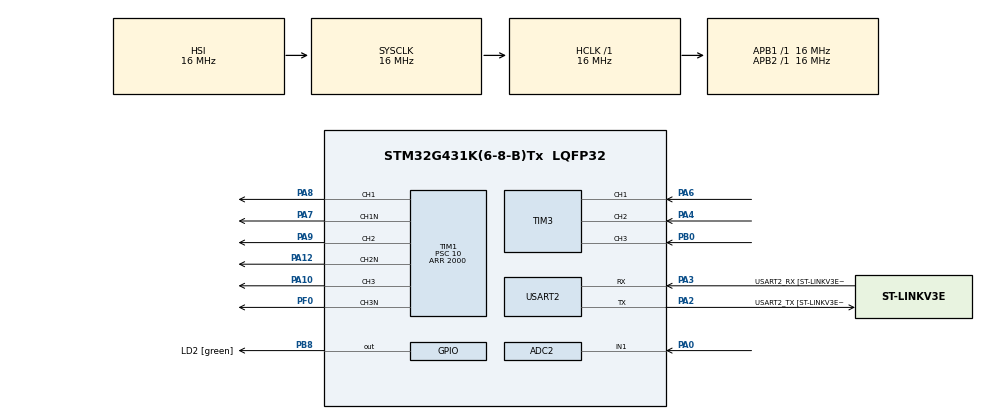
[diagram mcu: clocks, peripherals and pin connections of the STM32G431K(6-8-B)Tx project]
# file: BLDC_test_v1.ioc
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ADC2.Channel-0\#ChannelRegularConversion=ADC_CHANNEL_1
ADC2.NbrOfConversionFlag=1
ADC2.OffsetNumber-0\#ChannelRegularConversion=ADC_OFFSET_NONE
ADC2.Rank-0\#ChannelRegularConversion=1
ADC2.SamplingTime-0\#ChannelRegularConversion=ADC_SAMPLETIME_2CYCLES_5
Dma.Request0=TIM1_CH1
Dma.Request1=TIM1_CH2
Dma.TIM1_CH1.0.Direction=DMA_MEMORY_TO_PERIPH
Dma.TIM1_CH1.0.EventEnable=DISABLE
Dma.TIM1_CH1.0.Instance=DMA1_Channel1
Dma.TIM1_CH1.0.MemDataAlignment=DMA_MDATAALIGN_HALFWORD
Dma.TIM1_CH1.0.MemInc=DMA_MINC_ENABLE
Dma.TIM1_CH1.0.Mode=DMA_CIRCULAR
Dma.TIM1_CH1.0.PeriphDataAlignment=DMA_PDATAALIGN_HALFWORD
Dma.TIM1_CH1.0.PeriphInc=DMA_PINC_DISABLE
Dma.TIM1_CH1.0.Polarity=HAL_DMAMUX_REQ_GEN_RISING
Dma.TIM1_CH1.0.Priority=DMA_PRIORITY_LOW
Dma.TIM1_CH1.0.RequestNumber=1
Dma.TIM1_CH1.0.SignalID=NONE
Dma.TIM1_CH1.0.SyncEnable=ENABLE
Dma.TIM1_CH1.0.SyncPolarity=HAL_DMAMUX_SYNC_RISING
Dma.TIM1_CH1.0.SyncRequestNumber=1
Dma.TIM1_CH1.0.SyncSignalID=NONE
Dma.TIM1_CH2.1.Direction=DMA_MEMORY_TO_PERIPH
Dma.TIM1_CH2.1.EventEnable=DISABLE
Dma.TIM1_CH2.1.Instance=DMA1_Channel2
Dma.TIM1_CH2.1.MemDataAlignment=DMA_MDATAALIGN_HALFWORD
Dma.TIM1_CH2.1.MemInc=DMA_MINC_ENABLE
Dma.TIM1_CH2.1.Mode=DMA_NORMAL
Dma.TIM1_CH2.1.PeriphDataAlignment=DMA_PDATAALIGN_HALFWORD
Dma.TIM1_CH2.1.PeriphInc=DMA_PINC_DISABLE
Dma.TIM1_CH2.1.Polarity=HAL_DMAMUX_REQ_GEN_RISING
Dma.TIM1_CH2.1.Priority=DMA_PRIORITY_LOW
Dma.TIM1_CH2.1.RequestNumber=1
Dma.TIM1_CH2.1.SignalID=NONE
Dma.TIM1_CH2.1.SyncEnable=ENABLE
Dma.TIM1_CH2.1.SyncPolarity=HAL_DMAMUX_SYNC_RISING
Dma.TIM1_CH2.1.SyncRequestNumber=1
Dma.TIM1_CH2.1.SyncSignalID=NONE
Mcu.Family=STM32G4
Mcu.Name=STM32G431K(6-8-B)Tx
Mcu.Package=LQFP32
NVIC.DMA1_Channel1_IRQn=true\:0\:0\:false\:false\:true\:false\:true\:true
NVIC.DMA1_Channel2_IRQn=true\:0\:0\:false\:false\:true\:false\:true\:true
NVIC.DMAMUX_OVR_IRQn=true\:0\:0\:false\:false\:true\:false\:true\:true
NVIC.PriorityGroup=NVIC_PRIORITYGROUP_4
PA0.Mode=IN1-Single-Ended
PA0.Signal=ADC2_IN1
PA10.Signal=S_TIM1_CH3
PA12.Mode=PWM Generation2 CH2 CH2N
PA12.Signal=TIM1_CH2N
PA13.GPIO_Label=T_SWDIO
PA13.Mode=Serial_Wire
PA13.Signal=SYS_JTMS-SWDIO
PA14.GPIO_Label=T_SWCLK
PA14.Mode=Serial_Wire
PA14.Signal=SYS_JTCK-SWCLK
PA2.GPIO_Label=USART2_TX [ST-LINKV3E_VCP_RX]
PA2.Mode=Asynchronous
PA2.Signal=USART2_TX
PA3.GPIO_Label=USART2_RX [ST-LINKV3E_VCP_TX]
PA3.Mode=Asynchronous
PA3.Signal=USART2_RX
PA4.Signal=S_TIM3_CH2
PA6.Signal=S_TIM3_CH1
PA7.Mode=PWM Generation1 CH1 CH1N
PA7.Signal=TIM1_CH1N
PA8.Signal=S_TIM1_CH1
PA9.Signal=S_TIM1_CH2
PB0.Signal=S_TIM3_CH3
PB3.GPIO_Label=T_SWO
PB3.Signal=SYS_JTDO-SWO
PB8-BOOT0.GPIO_Label=LD2 [green]
PB8-BOOT0.Signal=GPIO_Output
PF0-OSC_IN.Mode=PWM Generation3 CH3 CH3N
PF0-OSC_IN.Signal=TIM1_CH3N
ProjectManager.HeapSize=0x200
ProjectManager.StackSize=0x400
ProjectManager.TargetToolchain=STM32CubeIDE
RCC.ADC12Freq_Value=16000000
RCC.AHBFreq_Value=16000000
RCC.APB1Freq_Value=16000000
RCC.APB1TimFreq_Value=16000000
RCC.APB2Freq_Value=16000000
RCC.APB2TimFreq_Value=16000000
RCC.CortexFreq_Value=16000000
RCC.EXTERNAL_CLOCK_VALUE=12288000
RCC.HCLKFreq_Value=16000000
RCC.HSE_VALUE=8000000
RCC.HSI48_VALUE=48000000
RCC.HSI_VALUE=16000000
RCC.LSE_VALUE=32768
RCC.PLLM=RCC_PLLM_DIV4
RCC.PLLN=85
RCC.SYSCLKFreq_VALUE=16000000
RCC.USBFreq_Value=170000000
RCC.VCOOutputFreq_Value=340000000
SH.S_TIM1_CH1.0=TIM1_CH1,PWM Generation1 CH1 CH1N
SH.S_TIM1_CH2.0=TIM1_CH2,PWM Generation2 CH2 CH2N
SH.S_TIM1_CH3.0=TIM1_CH3,PWM Generation3 CH3 CH3N
SH.S_TIM3_CH1.0=TIM3_CH1,Xored_Inputs_Hall_Sensor_Interface
SH.S_TIM3_CH2.0=TIM3_CH2,Xored_Inputs_Hall_Sensor_Interface
SH.S_TIM3_CH3.0=TIM3_CH3,Xored_Inputs_Hall_Sensor_Interface
TIM1.AutoReloadPreload=TIM_AUTORELOAD_PRELOAD_ENABLE
TIM1.Channel-PWM\ Generation1\ CH1\ CH1N=TIM_CHANNEL_1
TIM1.Channel-PWM\ Generation2\ CH2\ CH2N=TIM_CHANNEL_2
TIM1.Channel-PWM\ Generation3\ CH3\ CH3N=TIM_CHANNEL_3
TIM1.CounterMode=TIM_COUNTERMODE_UP
TIM1.PeriodNoDither=2000
TIM1.Prescaler=10
TIM3.CounterMode=TIM_COUNTERMODE_CENTERALIGNED1
USART2.VirtualMode-Asynchronous=VM_ASYNC
USART2.WordLength=WORDLENGTH_8B
VP_TIM1_VS_ClockSourceINT.Mode=Internal
VP_TIM3_VS_NoETR.Mode=ClockSourceETR_Mode2_Remap_TIM3
board=NUCLEO-G431KB

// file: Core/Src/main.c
/* USER CODE BEGIN Header */
/**
  ******************************************************************************
  * @file           : main.c
  * @brief          : Main program body
  ******************************************************************************
  * @attention
  *
  * Copyright (c) 2022 STMicroelectronics.
  * All rights reserved.
  *
  * This software is licensed under terms that can be found in the LICENSE file
  * in the root directory of this software component.
  * If no LICENSE file comes with this software, it is provided AS-IS.
  *
  ******************************************************************************
  */
/* USER CODE END Header */
#include "main.h"

/* USER CODE BEGIN Includes */
#include "dma.h"
/* USER CODE END Includes */

ADC_HandleTypeDef hadc2;

TIM_HandleTypeDef htim1;
TIM_HandleTypeDef htim3;
DMA_HandleTypeDef hdma_tim1_ch1;
DMA_HandleTypeDef hdma_tim1_ch2;

UART_HandleTypeDef huart2;

void SystemClock_Config(void);
static void MX_GPIO_Init(void);
static void MX_DMA_Init(void);
static void MX_USART2_UART_Init(void);
static void MX_TIM1_Init(void);
static void MX_TIM3_Init(void);
static void MX_ADC2_Init(void);

/* USER CODE BEGIN 0 */
//it for avoiding optimization on main last while loop
volatile uint8_t damy;

/* USER CODE END 0 */

int main(void)
{

  /* MCU Configuration--------------------------------------------------------*/

  /* Reset of all peripherals, Initializes the Flash interface and the Systick. */
  HAL_Init();

  /* Configure the system clock */
  SystemClock_Config();

  /* Initialize all configured peripherals */
  MX_GPIO_Init();
  MX_DMA_Init();
  MX_USART2_UART_Init();
  MX_TIM1_Init();
  MX_TIM3_Init();
  MX_ADC2_Init();
  /* USER CODE BEGIN 2 */
  ADC_Enable(&hadc2);
  main_cpp();
  /* USER CODE END 2 */

  /* Infinite loop */
  /* USER CODE BEGIN WHILE */
  while (1)
  {
    damy++;
    /* USER CODE END WHILE */

  }
}

void SystemClock_Config(void)
{
  RCC_OscInitTypeDef RCC_OscInitStruct = {0};
  RCC_ClkInitTypeDef RCC_ClkInitStruct = {0};

  /** Configure the main internal regulator output voltage
  */
  HAL_PWREx_ControlVoltageScaling(PWR_REGULATOR_VOLTAGE_SCALE1);

  /** Initializes the RCC Oscillators according to the specified parameters
  * in the RCC_OscInitTypeDef structure.
  */
  RCC_OscInitStruct.OscillatorType = RCC_OSCILLATORTYPE_HSI;
  RCC_OscInitStruct.HSIState = RCC_HSI_ON;
  RCC_OscInitStruct.HSICalibrationValue = RCC_HSICALIBRATION_DEFAULT;
  RCC_OscInitStruct.PLL.PLLState = RCC_PLL_NONE;
  if (HAL_RCC_OscConfig(&RCC_OscInitStruct) != HAL_OK)
  {
    Error_Handler();
  }

  /** Initializes the CPU, AHB and APB buses clocks
  */
  RCC_ClkInitStruct.ClockType = RCC_CLOCKTYPE_HCLK|RCC_CLOCKTYPE_SYSCLK
                              |RCC_CLOCKTYPE_PCLK1|RCC_CLOCKTYPE_PCLK2;
  RCC_ClkInitStruct.SYSCLKSource = RCC_SYSCLKSOURCE_HSI;
  RCC_ClkInitStruct.AHBCLKDivider = RCC_SYSCLK_DIV1;
  RCC_ClkInitStruct.APB1CLKDivider = RCC_HCLK_DIV1;
  RCC_ClkInitStruct.APB2CLKDivider = RCC_HCLK_DIV1;

  if (HAL_RCC_ClockConfig(&RCC_ClkInitStruct, FLASH_LATENCY_0) != HAL_OK)
  {
    Error_Handler();
  }
}

static void MX_ADC2_Init(void)
{

  ADC_ChannelConfTypeDef sConfig = {0};

  /** Common config
  */
  hadc2.Instance = ADC2;
  hadc2.Init.ClockPrescaler = ADC_CLOCK_SYNC_PCLK_DIV2;
  hadc2.Init.Resolution = ADC_RESOLUTION_12B;
  hadc2.Init.DataAlign = ADC_DATAALIGN_RIGHT;
  hadc2.Init.GainCompensation = 0;
  hadc2.Init.ScanConvMode = ADC_SCAN_DISABLE;
  hadc2.Init.EOCSelection = ADC_EOC_SINGLE_CONV;
  hadc2.Init.LowPowerAutoWait = DISABLE;
  hadc2.Init.ContinuousConvMode = DISABLE;
  hadc2.Init.NbrOfConversion = 1;
  hadc2.Init.DiscontinuousConvMode = DISABLE;
  hadc2.Init.ExternalTrigConv = ADC_SOFTWARE_START;
  hadc2.Init.ExternalTrigConvEdge = ADC_EXTERNALTRIGCONVEDGE_NONE;
  hadc2.Init.DMAContinuousRequests = DISABLE;
  hadc2.Init.Overrun = ADC_OVR_DATA_PRESERVED;
  hadc2.Init.OversamplingMode = DISABLE;
  if (HAL_ADC_Init(&hadc2) != HAL_OK)
  {
    Error_Handler();
  }

  /** Configure Regular Channel
  */
  sConfig.Channel = ADC_CHANNEL_1;
  sConfig.Rank = ADC_REGULAR_RANK_1;
  sConfig.SamplingTime = ADC_SAMPLETIME_2CYCLES_5;
  sConfig.SingleDiff = ADC_SINGLE_ENDED;
  sConfig.OffsetNumber = ADC_OFFSET_NONE;
  sConfig.Offset = 0;
  if (HAL_ADC_ConfigChannel(&hadc2, &sConfig) != HAL_OK)
  {
    Error_Handler();
  }

}

static void MX_TIM1_Init(void)
{

  TIM_ClockConfigTypeDef sClockSourceConfig = {0};
  TIM_MasterConfigTypeDef sMasterConfig = {0};
  TIM_OC_InitTypeDef sConfigOC = {0};
  TIM_BreakDeadTimeConfigTypeDef sBreakDeadTimeConfig = {0};

  htim1.Instance = TIM1;
  htim1.Init.Prescaler = 10;
  htim1.Init.CounterMode = TIM_COUNTERMODE_UP;
  htim1.Init.Period = 2000;
  htim1.Init.ClockDivision = TIM_CLOCKDIVISION_DIV1;
  htim1.Init.RepetitionCounter = 0;
  htim1.Init.AutoReloadPreload = TIM_AUTORELOAD_PRELOAD_ENABLE;
  if (HAL_TIM_Base_Init(&htim1) != HAL_OK)
  {
    Error_Handler();
  }
  sClockSourceConfig.ClockSource = TIM_CLOCKSOURCE_INTERNAL;
  if (HAL_TIM_ConfigClockSource(&htim1, &sClockSourceConfig) != HAL_OK)
  {
    Error_Handler();
  }
  if (HAL_TIM_PWM_Init(&htim1) != HAL_OK)
  {
    Error_Handler();
  }
  sMasterConfig.MasterOutputTrigger = TIM_TRGO_RESET;
  sMasterConfig.MasterOutputTrigger2 = TIM_TRGO2_RESET;
  sMasterConfig.MasterSlaveMode = TIM_MASTERSLAVEMODE_DISABLE;
  if (HAL_TIMEx_MasterConfigSynchronization(&htim1, &sMasterConfig) != HAL_OK)
  {
    Error_Handler();
  }
  sConfigOC.OCMode = TIM_OCMODE_PWM1;
  sConfigOC.Pulse = 0;
  sConfigOC.OCPolarity = TIM_OCPOLARITY_HIGH;
  sConfigOC.OCNPolarity = TIM_OCNPOLARITY_HIGH;
  sConfigOC.OCFastMode = TIM_OCFAST_DISABLE;
  sConfigOC.OCIdleState = TIM_OCIDLESTATE_RESET;
  sConfigOC.OCNIdleState = TIM_OCNIDLESTATE_RESET;
  if (HAL_TIM_PWM_ConfigChannel(&htim1, &sConfigOC, TIM_CHANNEL_1) != HAL_OK)
  {
    Error_Handler();
  }
  if (HAL_TIM_PWM_ConfigChannel(&htim1, &sConfigOC, TIM_CHANNEL_2) != HAL_OK)
  {
    Error_Handler();
  }
  if (HAL_TIM_PWM_ConfigChannel(&htim1, &sConfigOC, TIM_CHANNEL_3) != HAL_OK)
  {
    Error_Handler();
  }
  sBreakDeadTimeConfig.OffStateRunMode = TIM_OSSR_DISABLE;
  sBreakDeadTimeConfig.OffStateIDLEMode = TIM_OSSI_DISABLE;
  sBreakDeadTimeConfig.LockLevel = TIM_LOCKLEVEL_OFF;
  sBreakDeadTimeConfig.DeadTime = 0;
  sBreakDeadTimeConfig.BreakState = TIM_BREAK_DISABLE;
  sBreakDeadTimeConfig.BreakPolarity = TIM_BREAKPOLARITY_HIGH;
  sBreakDeadTimeConfig.BreakFilter = 0;
  sBreakDeadTimeConfig.BreakAFMode = TIM_BREAK_AFMODE_INPUT;
  sBreakDeadTimeConfig.Break2State = TIM_BREAK2_DISABLE;
  sBreakDeadTimeConfig.Break2Polarity = TIM_BREAK2POLARITY_HIGH;
  sBreakDeadTimeConfig.Break2Filter = 0;
  sBreakDeadTimeConfig.Break2AFMode = TIM_BREAK_AFMODE_INPUT;
  sBreakDeadTimeConfig.AutomaticOutput = TIM_AUTOMATICOUTPUT_DISABLE;
  if (HAL_TIMEx_ConfigBreakDeadTime(&htim1, &sBreakDeadTimeConfig) != HAL_OK)
  {
    Error_Handler();
  }
  HAL_TIM_MspPostInit(&htim1);

}

static void MX_TIM3_Init(void)
{

  TIM_ClockConfigTypeDef sClockSourceConfig = {0};
  TIM_HallSensor_InitTypeDef sConfig = {0};
  TIM_MasterConfigTypeDef sMasterConfig = {0};

  htim3.Instance = TIM3;
  htim3.Init.Prescaler = 0;
  htim3.Init.CounterMode = TIM_COUNTERMODE_CENTERALIGNED1;
  htim3.Init.Period = 65535;
  htim3.Init.ClockDivision = TIM_CLOCKDIVISION_DIV1;
  htim3.Init.AutoReloadPreload = TIM_AUTORELOAD_PRELOAD_DISABLE;
  if (HAL_TIM_Base_Init(&htim3) != HAL_OK)
  {
    Error_Handler();
  }
  sClockSourceConfig.ClockSource = TIM_CLOCKSOURCE_ETRMODE2;
  sClockSourceConfig.ClockPolarity = TIM_CLOCKPOLARITY_NONINVERTED;
  sClockSourceConfig.ClockPrescaler = TIM_CLOCKPRESCALER_DIV1;
  sClockSourceConfig.ClockFilter = 0;
  if (HAL_TIM_ConfigClockSource(&htim3, &sClockSourceConfig) != HAL_OK)
  {
    Error_Handler();
  }
  sConfig.IC1Polarity = TIM_ICPOLARITY_RISING;
  sConfig.IC1Prescaler = TIM_ICPSC_DIV1;
  sConfig.IC1Filter = 0;
  sConfig.Commutation_Delay = 0;
  if (HAL_TIMEx_HallSensor_Init(&htim3, &sConfig) != HAL_OK)
  {
    Error_Handler();
  }
  sMasterConfig.MasterOutputTrigger = TIM_TRGO_OC2REF;
  sMasterConfig.MasterSlaveMode = TIM_MASTERSLAVEMODE_DISABLE;
  if (HAL_TIMEx_MasterConfigSynchronization(&htim3, &sMasterConfig) != HAL_OK)
  {
    Error_Handler();
  }
  HAL_TIMEx_RemapConfig(&htim3, TIM_TIM3_ETR_COMP1);

}

static void MX_USART2_UART_Init(void)
{

  huart2.Instance = USART2;
  huart2.Init.BaudRate = 115200;
  huart2.Init.WordLength = UART_WORDLENGTH_8B;
  huart2.Init.StopBits = UART_STOPBITS_1;
  huart2.Init.Parity = UART_PARITY_NONE;
  huart2.Init.Mode = UART_MODE_TX_RX;
  huart2.Init.HwFlowCtl = UART_HWCONTROL_NONE;
  huart2.Init.OverSampling = UART_OVERSAMPLING_16;
  huart2.Init.OneBitSampling = UART_ONE_BIT_SAMPLE_DISABLE;
  huart2.Init.ClockPrescaler = UART_PRESCALER_DIV1;
  huart2.AdvancedInit.AdvFeatureInit = UART_ADVFEATURE_NO_INIT;
  if (HAL_UART_Init(&huart2) != HAL_OK)
  {
    Error_Handler();
  }
  if (HAL_UARTEx_SetTxFifoThreshold(&huart2, UART_TXFIFO_THRESHOLD_1_8) != HAL_OK)
  {
    Error_Handler();
  }
  if (HAL_UARTEx_SetRxFifoThreshold(&huart2, UART_RXFIFO_THRESHOLD_1_8) != HAL_OK)
  {
    Error_Handler();
  }
  if (HAL_UARTEx_DisableFifoMode(&huart2) != HAL_OK)
  {
    Error_Handler();
  }

}

static void MX_DMA_Init(void)
{

  /* DMA controller clock enable */
  __HAL_RCC_DMAMUX1_CLK_ENABLE();
  __HAL_RCC_DMA1_CLK_ENABLE();

  /* DMA interrupt init */
  /* DMA1_Channel1_IRQn interrupt configuration */
  HAL_NVIC_SetPriority(DMA1_Channel1_IRQn, 0, 0);
  HAL_NVIC_EnableIRQ(DMA1_Channel1_IRQn);
  /* DMA1_Channel2_IRQn interrupt configuration */
  HAL_NVIC_SetPriority(DMA1_Channel2_IRQn, 0, 0);
  HAL_NVIC_EnableIRQ(DMA1_Channel2_IRQn);
  /* DMAMUX_OVR_IRQn interrupt configuration */
  HAL_NVIC_SetPriority(DMAMUX_OVR_IRQn, 0, 0);
  HAL_NVIC_EnableIRQ(DMAMUX_OVR_IRQn);

}

static void MX_GPIO_Init(void)
{
  GPIO_InitTypeDef GPIO_InitStruct = {0};

  /* GPIO Ports Clock Enable */
  __HAL_RCC_GPIOF_CLK_ENABLE();
  __HAL_RCC_GPIOA_CLK_ENABLE();
  __HAL_RCC_GPIOB_CLK_ENABLE();

  /*Configure GPIO pin Output Level */
  HAL_GPIO_WritePin(LD2_GPIO_Port, LD2_Pin, GPIO_PIN_RESET);

  /*Configure GPIO pin : LD2_Pin */
  GPIO_InitStruct.Pin = LD2_Pin;
  GPIO_InitStruct.Mode = GPIO_MODE_OUTPUT_PP;
  GPIO_InitStruct.Pull = GPIO_NOPULL;
  GPIO_InitStruct.Speed = GPIO_SPEED_FREQ_LOW;
  HAL_GPIO_Init(LD2_GPIO_Port, &GPIO_InitStruct);

}

void Error_Handler(void)
{
  __disable_irq();
  while (1)
  {
  }
}
